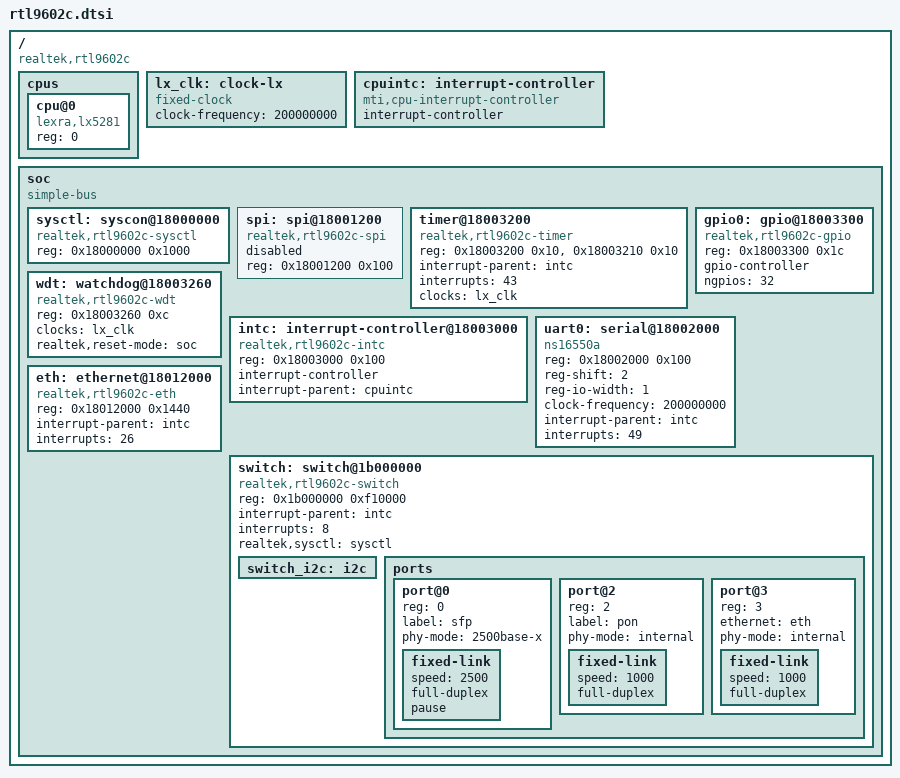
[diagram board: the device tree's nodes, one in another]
// SPDX-License-Identifier: GPL-2.0-only
/*
 * Realtek RTL9602C, a SoC for GPON optical network units: a Lexra LX5281
 * core, the peripherals the kernel drives, and an Ethernet switch with the
 * GPON MAC behind its PON port.
 */

#include <dt-bindings/gpio/gpio.h>

/ {
	#address-cells = <1>;
	#size-cells = <1>;
	compatible = "realtek,rtl9602c";

	/* One core; the kernel identifies it by its PRId, not by this node. */
	cpus {
		#address-cells = <1>;
		#size-cells = <0>;

		cpu@0 {
			device_type = "cpu";
			compatible = "lexra,lx5281";
			reg = <0>;
		};
	};

	/*
	 * The LX bus clock, 200 MHz (measured on this board), which the
	 * timers and the watchdog count.
	 */
	lx_clk: clock-lx {
		compatible = "fixed-clock";
		#clock-cells = <0>;
		clock-frequency = <200000000>;
	};

	/*
	 * The CPU's eight interrupt lines. The platform code sets up their
	 * domain without this node, so no interrupt resolves against it; it
	 * serves as the parent of intc.
	 */
	cpuintc: interrupt-controller {
		#address-cells = <0>;
		#interrupt-cells = <1>;
		interrupt-controller;
		compatible = "mti,cpu-interrupt-controller";
	};

	soc {
		compatible = "simple-bus";
		#address-cells = <1>;
		#size-cells = <1>;
		ranges;

		/*
		 * The system controller: the SoC's state and the enables of
		 * its on-chip blocks. The switch driver sets the enable in
		 * front of the PON MAC and its packet buffer here before its
		 * first access to them.
		 */
		sysctl: syscon@18000000 {
			compatible = "realtek,rtl9602c-sysctl", "syscon";
			reg = <0x18000000 0x1000>;
		};

		/*
		 * The controller of the SPI NOR flash the board boots from,
		 * the RTL838x one. The SoC also maps the flash for reading at
		 * 0x14000000; that window and this controller drive the same
		 * chip, so only one of them may be in use.
		 */
		spi: spi@18001200 {
			compatible = "realtek,rtl9602c-spi";
			reg = <0x18001200 0x100>;
			#address-cells = <1>;
			#size-cells = <0>;
			status = "disabled";
		};

		/*
		 * The general-purpose timers, 0x10 apart: timer 0 gives the
		 * clock events and timer 1 the clocksource.
		 */
		timer@18003200 {
			compatible = "realtek,rtl9602c-timer", "realtek,otto-timer";
			reg = <0x18003200 0x10>, <0x18003210 0x10>;
			interrupt-parent = <&intc>;
			interrupts = <43>;
			clocks = <&lx_clk>;
		};

		/*
		 * Three registers: keepalive, phase flags and control. The
		 * block raises no interrupt when a phase ends (measured on
		 * this board). An expiry resets the whole chip, the switch
		 * and the SerDes lane to the host included.
		 */
		wdt: watchdog@18003260 {
			compatible = "realtek,rtl9602c-wdt";
			reg = <0x18003260 0xc>;
			clocks = <&lx_clk>;
			realtek,reset-mode = "soc";
		};

		/*
		 * The second-level interrupt controller; its one cell is the
		 * source number, 0 to 63. It reaches the CPU on line 2, which
		 * the platform code fixes, so it has no interrupts property.
		 * The window ends at 0x100 because the block at 0x18003100 is
		 * a different controller. The platform code finds this node
		 * by its compatible to anchor the interrupt domain.
		 */
		intc: interrupt-controller@18003000 {
			compatible = "realtek,rtl9602c-intc";
			reg = <0x18003000 0x100>;
			interrupt-controller;
			#interrupt-cells = <1>;
			interrupt-parent = <&cpuintc>;
		};

		/*
		 * The GPIO bank. Only line 13 is used, by the switch, and no
		 * line as an interrupt; the width of 32 lines is not verified.
		 *
		 * Line n is taken to be bit n of a word in the CPU's own
		 * big-endian order, which the realtek,rtl9602c-gpio entry
		 * provides; not verified. The generic realtek,otto-gpio match
		 * assumes a byte-swapped order, which would put line 13 on
		 * bit 21, so it is not given as a fallback.
		 */
		gpio0: gpio@18003300 {
			compatible = "realtek,rtl9602c-gpio";
			reg = <0x18003300 0x1c>;
			gpio-controller;
			#gpio-cells = <2>;
			ngpios = <32>;
		};

		/*
		 * The console UART. The platform code registers the port
		 * itself, and no driver binds this node in this kernel. From
		 * this clock the 8250 core would compute the divisor the boot
		 * loader leaves, 109.
		 *
		 * The interrupt is the port's source in intc. Nothing reads
		 * it: the platform code registers the port with its interrupt
		 * before intc's interrupt domain exists.
		 */
		uart0: serial@18002000 {
			compatible = "ns16550a";
			reg = <0x18002000 0x100>;
			reg-shift = <2>;
			reg-io-width = <1>;
			clock-frequency = <200000000>;
			interrupt-parent = <&intc>;
			interrupts = <49>;
			status = "okay";
		};

		/* The CPU port's DMA engine, the switch's conduit */
		eth: ethernet@18012000 {
			compatible = "realtek,rtl9602c-eth";
			reg = <0x18012000 0x1440>;
			interrupt-parent = <&intc>;
			interrupts = <26>;
		};

		/*
		 * The Ethernet switch. Its register file, which ends at
		 * offset 0xf0d438, also holds the GPON MAC, the PON MAC with
		 * its packet buffer, the L3/NAT engine, the IEEE 1588 clock
		 * and the I2C masters of the optics.
		 */
		switch: switch@1b000000 {
			compatible = "realtek,rtl9602c-switch";

			reg = <0x1b000000 0xf10000>;

			/* One source for all of the switch's own interrupts */
			interrupt-parent = <&intc>;
			interrupts = <8>;

			/* Holds the enable in front of the PON MAC. */
			realtek,sysctl = <&sysctl>;

			/*
			 * The I2C master of the optics, master 1 of the two in
			 * the window. The board describes the devices on its
			 * bus.
			 */
			switch_i2c: i2c {
				#address-cells = <1>;
				#size-cells = <0>;
			};

			/*
			 * Port 1 exists in the silicon and is left out:
			 * nothing on this board is known to connect to it.
			 */
			ports {
				#address-cells = <1>;
				#size-cells = <0>;

				/*
				 * The SerDes lane to the host: no PHY, so a
				 * fixed link, whose real state the switch
				 * driver reports to phylink. The driver finds
				 * the host's setting of the lane itself,
				 * 2500BASE-X or 1000BASE-X, with in-band
				 * negotiation or without, and reports the
				 * speed of the setting found; it does not take
				 * the setting from this phy-mode.
				 * With "pause" in the fixed link the port sends
				 * and honours pause frames; without it it does
				 * neither. The lane is faster than the PON
				 * carries upstream, so a host that sends in
				 * bursts fills the switch's buffer. With the
				 * port sending pause frames the PON port's
				 * queue may fill to the pause marks, which
				 * the PON driver sets; without them the
				 * switch drops frames at about half that
				 * depth. A host that honours the pause frames
				 * slows down instead, and one that ignores
				 * them sees no change.
				 */
				port@0 {
					reg = <0>;
					label = "sfp";
					phy-mode = "2500base-x";

					fixed-link {
						speed = <2500>;
						full-duplex;
						pause;
					};
				};

				/*
				 * The PON port, behind which the GPON MAC
				 * sits; bringing it up starts the ONU's
				 * activation.
				 */
				port@2 {
					reg = <2>;
					label = "pon";
					phy-mode = "internal";

					fixed-link {
						speed = <1000>;
						full-duplex;
					};
				};

				/* The CPU port */
				port@3 {
					reg = <3>;
					ethernet = <&eth>;
					phy-mode = "internal";

					fixed-link {
						speed = <1000>;
						full-duplex;
					};
				};
			};
		};
	};
};
